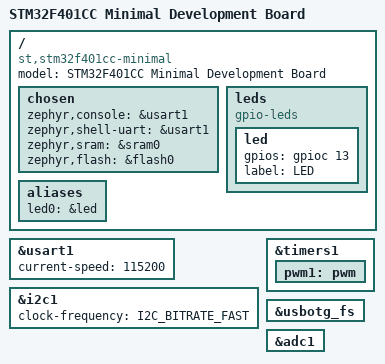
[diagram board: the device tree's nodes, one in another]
/dts-v1/;
#include <st/f4/stm32f401Xc.dtsi>

/ {
	model = "STM32F401CC Minimal Development Board";
	compatible = "st,stm32f401cc-minimal", "st,stm32f401";

	chosen {
		zephyr,console = &usart1;
		zephyr,shell-uart = &usart1;
		zephyr,sram = &sram0;
		zephyr,flash = &flash0;
		//zephyr,ccm = &ccm0;
	};

	leds { 
		compatible = "gpio-leds";
		led: led {
			gpios = <&gpioc 13 GPIO_ACTIVE_HIGH>;
			label = "LED";
		};
	};
	aliases {
		led0 = &led;
	};
};

&usart1 {
	current-speed = <115200>;
	status = "okay";
};

&i2c1 {
	status = "okay";
	clock-frequency = <I2C_BITRATE_FAST>;
};

&timers1 {
	status = "okay";
	pwm1: pwm {
		status = "okay";
	};
};

&usbotg_fs {
	status = "okay";
};
&adc1 {
	status = "okay";
};
